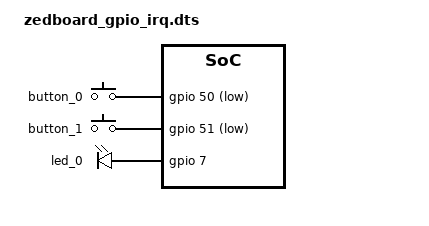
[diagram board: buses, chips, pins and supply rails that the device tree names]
/ {
    gpio_keys {
        compatible = "gpio-keys";
        pinctrl-names = "default";
        pinctrl-0 = <&gpio_keys_pins>;

        button_0 {
            label = "button_0";
            gpios = <&gpio 50 GPIO_ACTIVE_LOW>;
            linux,code = <KEY_1>;
            interrupt-parent = <&gpio>;
            interrupts = <50 IRQ_TYPE_EDGE_RISING>;
        };

        button_1 {
            label = "button_1";
            gpios = <&gpio 51 GPIO_ACTIVE_LOW>;
            linux,code = <KEY_2>;
            interrupt-parent = <&gpio>;
            interrupts = <51 IRQ_TYPE_EDGE_RISING>;
        };
    };

    gpio-leds {
        compatible = "gpio-leds";
        led_0 {
            label = "led_0";
            gpios = <&gpio 7 GPIO_ACTIVE_HIGH>;
            default-state = "off";
        };
    };
};

